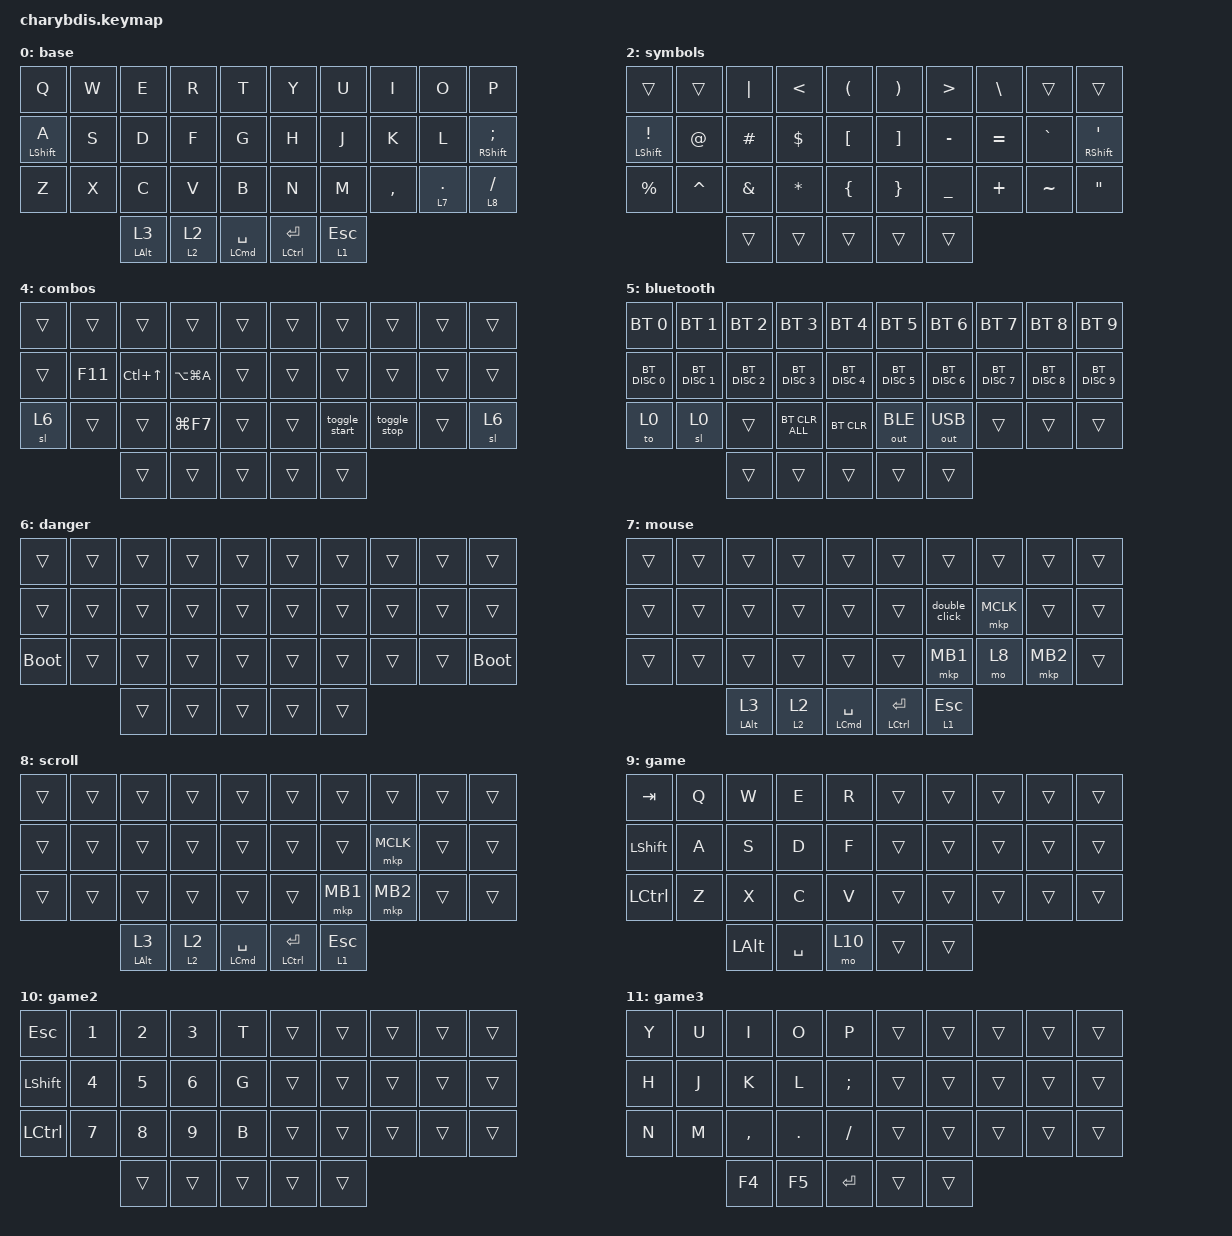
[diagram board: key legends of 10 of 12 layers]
#include <behaviors/mouse_keys.dtsi>
#include <behaviors.dtsi>
#include <dt-bindings/zmk/bt.h>
#include <dt-bindings/zmk/keys.h>
#include <dt-bindings/zmk/mouse.h>
#include <dt-bindings/zmk/outputs.h>

#define U_TAPPING_TERM 200

/ {
    chosen { zmk,matrix_transform = &five_column_transform; };
};

&sk { quick-release; };

/ {
    combos {
        compatible = "zmk,combos";

        tab {
            bindings = <&kp TAB>;
            key-positions = <13 12>;
            layers = <0 1 2 3 4 7 8 5 6>;
        };

        backspace {
            bindings = <&kp BACKSPACE>;
            key-positions = <16 17>;
        };

        delete {
            bindings = <&kp DELETE>;
            key-positions = <18 17>;
        };

        reset_layers {
            bindings = <&to 0>;
            key-positions = <0 9>;
        };

        left_shift {
            bindings = <&hold_sticky_key LEFT_SHIFT LEFT_SHIFT>;
            key-positions = <22 23>;
        };

        shift_alt {
            bindings = <&hold_sticky_key LS(LEFT_ALT) LS(LEFT_ALT)>;
            key-positions = <11 12>;
            layers = <0 1>;
        };

        ctrl_alt {
            bindings = <&hold_sticky_key LC(LEFT_ALT) LC(LEFT_ALT)>;
            key-positions = <21 22>;
            layers = <0 1>;
        };

        shift_alt_cmd {
            bindings = <&hold_sticky_key LS(LA(LCMD)) LS(LA(LCMD))>;
            key-positions = <10 11 12>;
            layers = <0 1>;
        };

        ctrl_alt_cmd {
            bindings = <&hold_sticky_key LC(LA(LCMD)) LA(LC(LCMD))>;
            key-positions = <20 21 22>;
            layers = <0 1>;
        };

        meta {
            bindings = <&hold_sticky_key LS(LA(LC(LEFT_GUI))) LS(LA(LC(LEFT_GUI)))>;
            key-positions = <13 10 11 12>;
            layers = <0 1>;
        };

        left_gui_space {
            bindings = <&kp LG(SPACE)>;
            key-positions = <31 32>;
        };

        cmd_alt {
            bindings = <&kp LA(LCMD)>;
            key-positions = <30 32>;
        };

        toggle_mouse_layer {
            bindings = <&mkp LCLK>;
            key-positions = <26 27>;
        };

        toggle_scroll_layer {
            bindings = <&mkp RCLK>;
            key-positions = <27 28>;
        };

        to_base_layer {
            bindings = <&to 0>;
            key-positions = <25 26>;
        };

        to_base_layer_alt_2 {
            bindings = <&to 8>;
            key-positions = <26 28>;
        };

        to_game_3 {
            bindings = <&sl 11>;
            key-positions = <12 13>;
            layers = <9 10 11>;
        };
    };

    behaviors {
        ctrl_alt_dance: ctrl_alt_dance {
            compatible = "zmk,behavior-tap-dance";
            label = "CTRL_ALT_DANCE";
            #binding-cells = <0>;
            tapping-term-ms = <200>;
            bindings = <&kp LCTRL>, <&kp LEFT_ALT>;
        };

        hold_tap: hold_tap {
            compatible = "zmk,behavior-hold-tap";
            label = "HOLD_TAP";
            bindings = <&kp>, <&kp>;

            #binding-cells = <2>;
            tapping-term-ms = <200>;
            flavor = "tap-preferred";
            quick-tap-ms = <100>;
        };

        layer_tap: layer_tap {
            compatible = "zmk,behavior-hold-tap";
            label = "LAYER_TAP";
            #binding-cells = <2>;
            tapping-term-ms = <200>;
            flavor = "balanced";
            bindings = <&mo>, <&kp>;
        };

        speclayers: speclayers {
            compatible = "zmk,behavior-tap-dance";
            label = "SPECLAYERS";
            #binding-cells = <0>;
            bindings = <&sl 3>, <&sl 4>;
        };

        hold_sticky_key: hold_sticky_key {
            compatible = "zmk,behavior-hold-tap";
            label = "HOLD_STICKY_KEY";
            bindings = <&kp>, <&sk>;

            #binding-cells = <2>;
            tapping-term-ms = <200>;
            flavor = "tap-preferred";
            quick-tap-ms = <100>;
        };

        hold_spec_layer: hold_spec_layer {
            compatible = "zmk,behavior-hold-tap";
            label = "HOLD_SPEC_LAYER";
            bindings = <&kp>, <&speclayers>;

            #binding-cells = <2>;
            tapping-term-ms = <200>;
            quick-tap-ms = <100>;
            flavor = "tap-preferred";
        };

        left_shift_caps: left_shift_caps {
            compatible = "zmk,behavior-tap-dance";
            label = "LEFT_SHIFT_CAPS";
            #binding-cells = <0>;
            bindings = <&hold_sticky_key LEFT_SHIFT LEFT_SHIFT>, <&caps_word>;
        };

        right_shift_caps: right_shift_caps {
            compatible = "zmk,behavior-tap-dance";
            label = "RIGHT_SHIFT_CAPS";
            #binding-cells = <0>;
            bindings = <&hold_sticky_key RIGHT_SHIFT RIGHT_SHIFT>, <&caps_word>;
        };

        hold_sticky_layer: hold_sticky_layer {
            compatible = "zmk,behavior-hold-tap";
            label = "HOLD_STICKY_LAYER";
            bindings = <&kp>, <&sl>;

            #binding-cells = <2>;
            tapping-term-ms = <200>;
            flavor = "balanced";
        };

        hold_or_sticky_layer: hold_or_sticky_layer {
            compatible = "zmk,behavior-hold-tap";
            label = "HOLD_OR_STICKY_LAYER";
            bindings = <&mo>, <&sl>;

            #binding-cells = <2>;
            tapping-term-ms = <100>;
            flavor = "tap-preferred";
        };

        hold_to_layer: hold_to_layer {
            compatible = "zmk,behavior-hold-tap";
            label = "HOLD_TO_LAYER";
            bindings = <&kp>, <&to>;

            #binding-cells = <2>;
            flavor = "balanced";
            tapping-term-ms = <200>;
        };
    };

    macros {
        toggle_start: toggle_start {
            compatible = "zmk,behavior-macro";
            #binding-cells = <0>;
            bindings =
                <&macro_tap>,
                <&kp LS(LA(LC(LG(T))))>,
                <&macro_wait_time 300>,
                <&macro_tap>,
                <&kp RG(O) &kp LG(TAB)>;

            label = "TOGGLE_START";
            wait-ms = <1000>;
            tap-ms = <10>;
        };

        toggle_stop: toggle_stop {
            compatible = "zmk,behavior-macro";
            #binding-cells = <0>;
            bindings =
                <&macro_tap>,
                <&kp LS(LA(LC(LG(T))))>,
                <&macro_wait_time 300>,
                <&macro_tap>,
                <&kp RG(S) &kp LG(TAB)>;

            label = "TOGGLE_STOP";
            wait-ms = <1000>;
            tap-ms = <10>;
        };

        tripple_escape: tripple_escape {
            compatible = "zmk,behavior-macro";
            #binding-cells = <0>;
            bindings = <&macro_tap>, <&kp ESCAPE &kp ESCAPE &kp ESCAPE>;

            label = "TRIPPLE_ESCAPE";
        };

        quite_vim: quite_vim {
            compatible = "zmk,behavior-macro";
            #binding-cells = <0>;
            bindings = <&macro_tap>, <&kp COLON &kp Q &kp A &kp ENTER>;

            label = "QUITE_VIM";
        };

        arrow: arrow {
            compatible = "zmk,behavior-macro";
            #binding-cells = <0>;
            bindings = <&kp EQUAL &kp GREATER_THAN>;
            label = "ARROW";
        };

        task: task {
            compatible = "zmk,behavior-macro";
            #binding-cells = <0>;
            bindings = <&kp MINUS &kp SPACE &kp LBKT &kp SPACE &kp RIGHT_BRACKET &kp SPACE>;
            label = "TASK";
        };

        to_mouse_layer: to_mouse_layer {
            compatible = "zmk,behavior-macro";
            #binding-cells = <0>;
            bindings = <&to 0 &tog 7>;
            label = "TO_MOUSE_LAYER";
        };

        to_scroll_layer: to_scroll_layer {
            compatible = "zmk,behavior-macro";
            #binding-cells = <0>;
            bindings = <&to 0 &tog 8>;
            label = "TO_SCROLL_LAYER";
        };

        double_click: double_click {
            compatible = "zmk,behavior-macro";
            #binding-cells = <0>;
            bindings = <&mkp MB1 &mkp MB1>;
            label = "DOUBLE_CLICK";
            wait-ms = <50>;
        };

        cmd_tab: cmd_tab {
            compatible = "zmk,behavior-mod-morph";
            label = "CMD_TAB";
            bindings = <&layer_tap 1 ESCAPE>, <&kp TAB>;

            #binding-cells = <0>;
            mods = <(MOD_LGUI|MOD_RGUI|MOD_LALT|MOD_RALT)>;
            keep-mods = <(MOD_LALT|MOD_LGUI|MOD_RALT|MOD_RGUI)>;
        };

        layer_mkp: layer_mkp {
            compatible = "zmk,behavior-hold-tap";
            label = "LAYER_MKP";
            bindings = <&mo>, <&mkp>;

            #binding-cells = <2>;
            tapping-term-ms = <100>;
        };
    };

    keymap {
        compatible = "zmk,keymap";

        base {
            bindings = <
  &kp Q                   &kp W  &kp E                          &kp R                      &kp T                           &kp Y                         &kp U                &kp I      &kp O                &kp P
  &hold_tap LEFT_SHIFT A  &kp S  &kp D                          &kp F                      &kp G                           &kp H                         &kp J                &kp K      &kp L                &hold_tap RIGHT_SHIFT SEMICOLON
  &kp Z                   &kp X  &kp C                          &kp V                      &kp B                           &kp N                         &kp M                &kp COMMA  &layer_tap 7 PERIOD  &layer_tap 8 SLASH
                                 &hold_sticky_layer LEFT_ALT 3  &hold_or_sticky_layer 2 2  &hold_tap LEFT_COMMAND SPACE    &hold_tap LEFT_CONTROL ENTER  &layer_tap 1 ESCAPE
            >;
        };

        navigation {
            bindings = <
  &kp N1            &kp N2             &kp N3           &kp N4      &kp N5           &kp N6    &kp N7    &kp N8  &kp N9     &kp N0
  &caps_word        &kp LC(N9)         &kp LC(N8)       &kp LC(N7)  &kp PG_UP        &kp LEFT  &kp DOWN  &kp UP  &kp RIGHT  &trans
  &kp LEFT_CONTROL  &kp C_VOLUME_DOWN  &kp C_VOLUME_UP  &kp LC(A)   &kp PAGE_DOWN    &trans    &trans    &trans  &trans     &trans
                                       &trans           &trans      &trans           &trans
            >;
        };

        symbols {
            bindings = <
  &trans                     &trans       &kp PIPE       &kp LESS_THAN  &kp LEFT_PARENTHESIS    &kp RIGHT_PARENTHESIS  &kp GREATER_THAN  &kp BACKSLASH  &trans     &trans
  &hold_tap LEFT_SHIFT EXCL  &kp AT_SIGN  &kp HASH       &kp DOLLAR     &kp LEFT_BRACKET        &kp RIGHT_BRACKET      &kp MINUS         &kp EQUAL      &kp GRAVE  &hold_tap RIGHT_SHIFT SQT
  &kp PERCENT                &kp CARET    &kp AMPERSAND  &kp ASTERISK   &kp LEFT_BRACE          &kp RIGHT_BRACE        &kp UNDERSCORE    &kp PLUS       &kp TILDE  &kp DOUBLE_QUOTES
                                          &trans         &trans         &trans                  &trans                 &trans
            >;
        };

        functions {
            bindings = <
  &kp F1                 &kp F2                 &kp F3                 &kp F4                 &kp F5                   &kp F6          &kp F7            &kp F8      &kp F9   &kp F10
  &kp LS(LA(LC(LG(A))))  &kp LS(LA(LC(LG(S))))  &kp LC(LA(LS(LG(D))))  &kp LS(LA(LC(LG(F))))  &kp LS(LC(LG(LA(G))))    &trans          &kp C_MUTE        &trans      &kp F11  &kp F12
  &kp LS(LA(LC(LG(Z))))  &kp LS(LC(LA(LG(X))))  &kp LS(LA(LC(LG(C))))  &kp LS(LA(LC(LG(V))))  &kp LS(LA(LC(LG(B))))    &kp C_PREVIOUS  &kp C_PLAY_PAUSE  &kp C_NEXT  &sl 5    &to 9
                                                &sl 4                  &trans                 &trans                   &trans          &trans
            >;
        };

        combos {
            bindings = <
  &trans  &trans   &trans            &trans         &trans    &trans  &trans         &trans        &trans  &trans
  &trans  &kp F11  &kp LC(UP_ARROW)  &kp LA(LG(A))  &trans    &trans  &trans         &trans        &trans  &trans
  &sl 6   &trans   &trans            &kp LG(F7)     &trans    &trans  &toggle_start  &toggle_stop  &trans  &sl 6
                   &trans            &trans         &trans    &trans  &trans
            >;
        };

        bluetooth {
            bindings = <
  &bt BT_SEL 0   &bt BT_SEL 1   &bt BT_SEL 2   &bt BT_SEL 3    &bt BT_SEL 4     &bt BT_SEL 5   &bt BT_SEL 6   &bt BT_SEL 7   &bt BT_SEL 8   &bt BT_SEL 9
  &bt BT_DISC 0  &bt BT_DISC 1  &bt BT_DISC 2  &bt BT_DISC 3   &bt BT_DISC 4    &bt BT_DISC 5  &bt BT_DISC 6  &bt BT_DISC 7  &bt BT_DISC 8  &bt BT_DISC 9
  &to 0          &sl 0          &trans         &bt BT_CLR_ALL  &bt BT_CLR       &out OUT_BLE   &out OUT_USB   &trans         &trans         &trans
                                &trans         &trans          &trans           &trans         &trans
            >;
        };

        danger {
            bindings = <
  &trans       &trans  &trans  &trans  &trans    &trans  &trans  &trans  &trans  &trans
  &trans       &trans  &trans  &trans  &trans    &trans  &trans  &trans  &trans  &trans
  &bootloader  &trans  &trans  &trans  &trans    &trans  &trans  &trans  &trans  &bootloader
                       &trans  &trans  &trans    &trans  &trans
            >;
        };

        mouse {
            bindings = <
  &trans  &trans  &trans                         &trans                     &trans                          &trans                        &trans               &trans     &trans    &trans
  &trans  &trans  &trans                         &trans                     &trans                          &trans                        &double_click        &mkp MCLK  &trans    &trans
  &trans  &trans  &trans                         &trans                     &trans                          &trans                        &mkp MB1             &mo 8      &mkp MB2  &trans
                  &hold_sticky_layer LEFT_ALT 3  &hold_or_sticky_layer 2 2  &hold_tap LEFT_COMMAND SPACE    &hold_tap LEFT_CONTROL ENTER  &layer_tap 1 ESCAPE
            >;
        };

        scroll {
            bindings = <
  &trans  &trans  &trans                         &trans                     &trans                          &trans                        &trans               &trans     &trans  &trans
  &trans  &trans  &trans                         &trans                     &trans                          &trans                        &trans               &mkp MCLK  &trans  &trans
  &trans  &trans  &trans                         &trans                     &trans                          &trans                        &mkp MB1             &mkp MB2   &trans  &trans
                  &hold_sticky_layer LEFT_ALT 3  &hold_or_sticky_layer 2 2  &hold_tap LEFT_COMMAND SPACE    &hold_tap LEFT_CONTROL ENTER  &layer_tap 1 ESCAPE
            >;
        };

        game {
            bindings = <
  &kp TAB    &kp Q  &kp W     &kp E      &kp R     &trans  &trans  &trans  &trans  &trans
  &kp LSHFT  &kp A  &kp S     &kp D      &kp F     &trans  &trans  &trans  &trans  &trans
  &kp LCTRL  &kp Z  &kp X     &kp C      &kp V     &trans  &trans  &trans  &trans  &trans
                    &kp LALT  &kp SPACE  &mo 10    &trans  &trans
            >;
        };

        game2 {
            bindings = <
  &kp ESC    &kp N1  &kp N2  &kp N3  &kp T     &trans  &trans  &trans  &trans  &trans
  &kp LSHFT  &kp N4  &kp N5  &kp N6  &kp G     &trans  &trans  &trans  &trans  &trans
  &kp LCTRL  &kp N7  &kp N8  &kp N9  &kp B     &trans  &trans  &trans  &trans  &trans
                     &trans  &trans  &trans    &trans  &trans
            >;
        };

        game3 {
            bindings = <
  &kp Y  &kp U  &kp I      &kp O    &kp P        &trans  &trans  &trans  &trans  &trans
  &kp H  &kp J  &kp K      &kp L    &kp SEMI     &trans  &trans  &trans  &trans  &trans
  &kp N  &kp M  &kp COMMA  &kp DOT  &kp FSLH     &trans  &trans  &trans  &trans  &trans
                &kp F4     &kp F5   &kp ENTER    &trans  &trans
            >;
        };
    };
};

